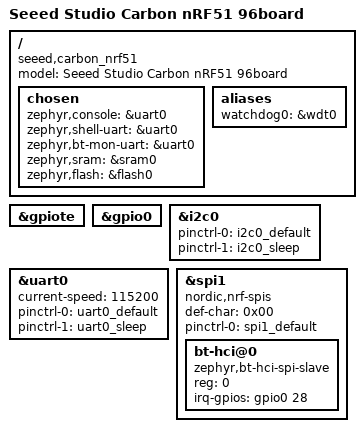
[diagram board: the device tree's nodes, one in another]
/*
 * Copyright (c) 2017 Linaro Limited
 *
 * SPDX-License-Identifier: Apache-2.0
 */

/dts-v1/;
#include <nordic/nrf51822_qfac.dtsi>
#include "96b_carbon_nrf51822-pinctrl.dtsi"

/ {
	model = "Seeed Studio Carbon nRF51 96board";
	compatible = "seeed,carbon_nrf51";

	chosen {
		zephyr,console = &uart0;
		zephyr,shell-uart = &uart0;
		zephyr,bt-mon-uart = &uart0;
		zephyr,sram = &sram0;
		zephyr,flash = &flash0;
	};

	aliases {
		watchdog0 = &wdt0;
	};
};

&gpiote {
	status = "okay";
};

&gpio0 {
	status = "okay";
};

&i2c0 {
	status = "okay";
	pinctrl-0 = <&i2c0_default>;
	pinctrl-1 = <&i2c0_sleep>;
	pinctrl-names = "default", "sleep";
};

&uart0 {
	current-speed = <115200>;
	status = "okay";
	pinctrl-0 = <&uart0_default>;
	pinctrl-1 = <&uart0_sleep>;
	pinctrl-names = "default", "sleep";
};

&spi1 {
	compatible = "nordic,nrf-spis";
	status = "okay";
	def-char = <0x00>;

	pinctrl-0 = <&spi1_default>;
	pinctrl-names = "default";

	bt-hci@0 {
		compatible = "zephyr,bt-hci-spi-slave";
		reg = <0>;
		irq-gpios = <&gpio0 28 (GPIO_ACTIVE_HIGH | GPIO_PULL_DOWN)>;
	};
};
